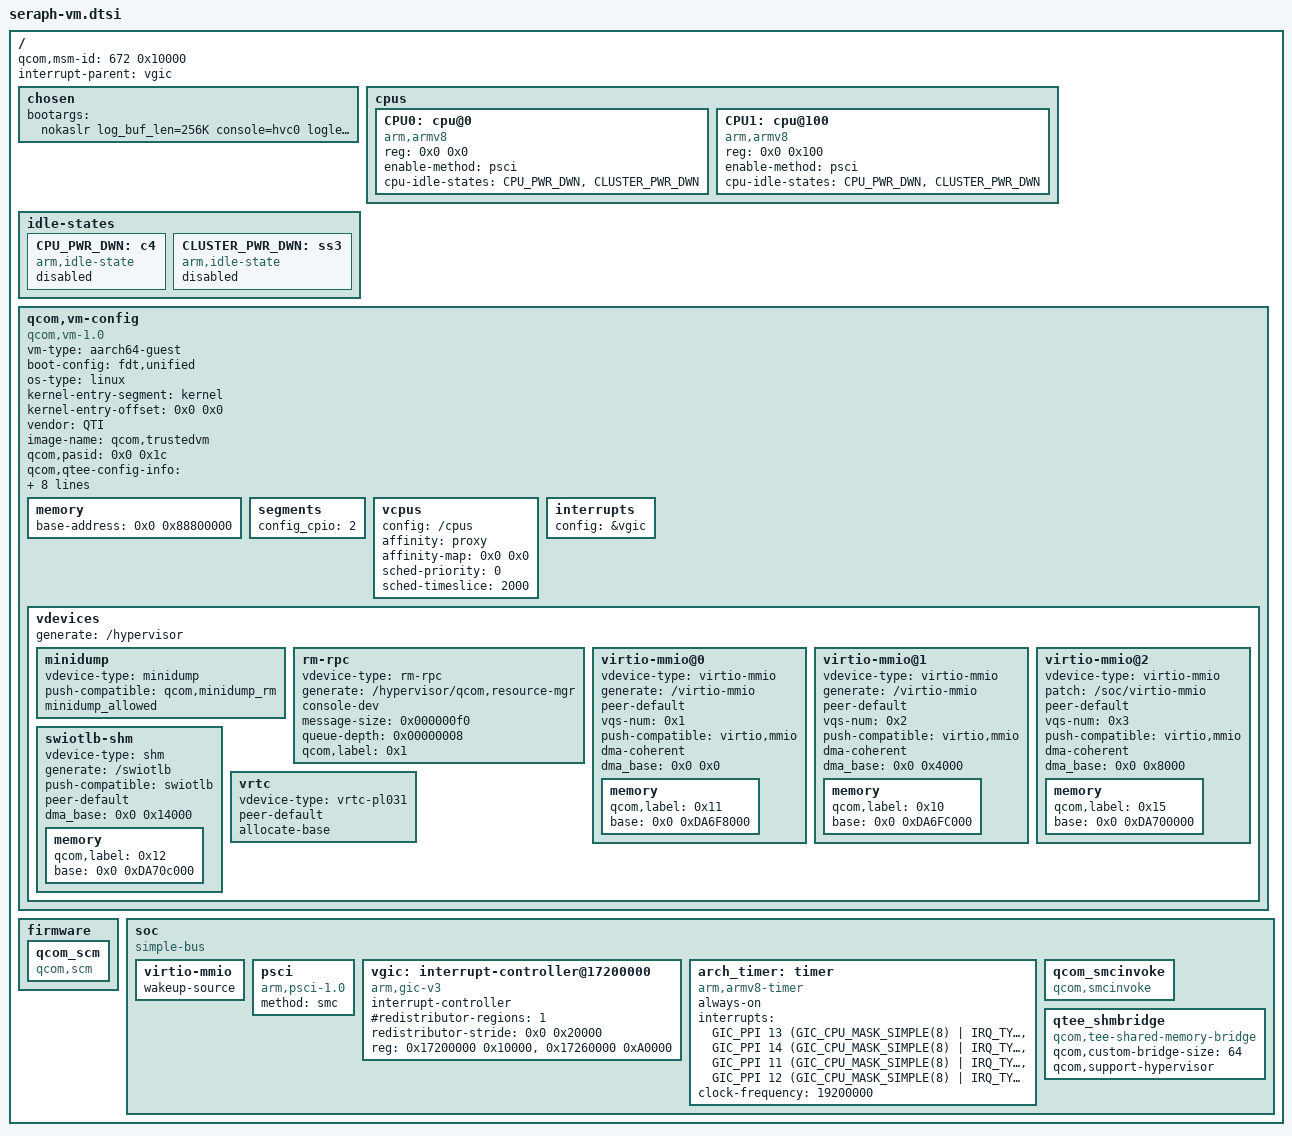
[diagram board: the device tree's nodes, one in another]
#include <dt-bindings/interrupt-controller/arm-gic.h>
#include <dt-bindings/clock/qcom,gcc-seraph.h>

/ {
	#address-cells = <0x2>;
	#size-cells = <0x2>;
	qcom,msm-id = <672 0x10000>;
	interrupt-parent = <&vgic>;
	chosen {
		bootargs = "nokaslr log_buf_len=256K console=hvc0 loglevel=8 swiotlb=noforce";
	};

	cpus {
		#address-cells = <0x2>;
		#size-cells = <0x0>;
		CPU0: cpu@0 {
			compatible = "arm,armv8";
			reg = <0x0 0x0>;
			device_type = "cpu";
			enable-method = "psci";
			cpu-idle-states = <&CPU_PWR_DWN
					   &CLUSTER_PWR_DWN>;
		};

		CPU1: cpu@100 {
			compatible = "arm,armv8";
			reg = <0x0 0x100>;
			device_type = "cpu";
			enable-method = "psci";
			cpu-idle-states = <&CPU_PWR_DWN
					   &CLUSTER_PWR_DWN>;
		};
	};

	idle-states {
		CPU_PWR_DWN: c4 {  /* Using Medium C4 latencies */
			compatible = "arm,idle-state";
			status = "disabled";
		};

		CLUSTER_PWR_DWN: ss3 { /* C4+CL5+SS3 */
			compatible = "arm,idle-state";
			status = "disabled";
		};
	};

	qcom,vm-config {
		compatible = "qcom,vm-1.0";
		vm-type = "aarch64-guest";
		boot-config = "fdt,unified";
		os-type = "linux";
		kernel-entry-segment = "kernel";
		kernel-entry-offset = <0x0 0x0>;
		vendor = "QTI";
		image-name = "qcom,trustedvm";
		qcom,pasid = <0x0 0x1c>;
		qcom,qtee-config-info = "p=3,9,C,39,77,78,7C,8F,96,97,C8,FE,10C,11B,159,199,47E,7F1,CDF;";
		qcom,secdomain-ids = <45>;
		qcom,primary-vm-index = <0>;
		vm-uri = "vmuid/trusted-ui";
		vm-guid = "598085da-c516-5b25-a9c1-927a02819770";
		qcom,sensitive;
		vm-attrs = "context-dump", "crash-restart";
		/* For LEVM por usecases is QUP1_SE4 and QUP2_SE7.
		 * QUP1_SE4: GPII5 : IRQ_316
		 * QUP2_SE7: GPII5 : IRQ_625
		 *
		if you need this, add IRQ here
		gic-irq-ranges = <316 316
				  625 625
				  279 279>;
		*/
		gic-irq-ranges = <>;
		memory {
			#address-cells = <0x2>;
			#size-cells = <0x0>;
			/*
			 * IPA address linux image is loaded at. Must be within
			 * first 1GB due to memory hotplug requirement.
			 */
			base-address = <0x0 0x88800000 >;
		};

		segments {
			config_cpio = <2>;
		};

		vcpus {
			config = "/cpus";
			affinity = "proxy";
			affinity-map = <0x0 0x0>;
			sched-priority = <0>;       /* relative to PVM */
			sched-timeslice = <2000>;   /* in ms */
		};

		interrupts {
			config = &vgic;
		};

		vdevices {
			generate = "/hypervisor";
			minidump {
				vdevice-type = "minidump";
				push-compatible = "qcom,minidump_rm";
				minidump_allowed;
			};

			rm-rpc {
				vdevice-type = "rm-rpc";
				generate = "/hypervisor/qcom,resource-mgr";
				console-dev;
				message-size = <0x000000f0>;
				queue-depth = <0x00000008>;
				qcom,label = <0x1>;
			};

			virtio-mmio@0 {
				vdevice-type = "virtio-mmio";
				generate = "/virtio-mmio";
				peer-default;
				vqs-num = <0x1>;
				push-compatible = "virtio,mmio";
				dma-coherent;
				dma_base = <0x0 0x0>;
				memory {
					qcom,label = <0x11>;			//for persist.img
					#address-cells = <0x2>;
					base = <0x0 0xDA6F8000>;
				};
			};

			virtio-mmio@1 {
				vdevice-type = "virtio-mmio";
				generate = "/virtio-mmio";
				peer-default;
				vqs-num = <0x2>;
				push-compatible = "virtio,mmio";
				dma-coherent;
				dma_base = <0x0 0x4000>;
				memory {
					qcom,label = <0x10>;			//for system.img
					#address-cells = <0x2>;
					base = <0x0 0xDA6FC000>;
				};
			};

			virtio-mmio@2 {
				vdevice-type = "virtio-mmio";
				patch = "/soc/virtio-mmio";
				peer-default;
				vqs-num = <0x3>;
				push-compatible = "virtio,mmio";
				dma-coherent;
				dma_base = <0x0 0x8000>;
				memory {
					qcom,label = <0x15>;			//for virtio-vsock
					#address-cells = <0x2>;
					base = <0x0 0xDA700000>;
				};
			};

			swiotlb-shm {
				vdevice-type = "shm";
				generate = "/swiotlb";
				push-compatible = "swiotlb";
				peer-default;
				dma_base = <0x0 0x14000>;
				memory {
					qcom,label = <0x12>;
					#address-cells = <0x2>;
					base = <0x0 0xDA70c000>;
				};
			};

			vrtc {
				vdevice-type = "vrtc-pl031";
				peer-default;
				allocate-base;
			};
		};
	};

	firmware: firmware {
		qcom_scm: qcom_scm {
			compatible = "qcom,scm";
		};
	};

	soc: soc { };

};

&soc {
	#address-cells = <1>;
	#size-cells = <1>;
	ranges = <0 0 0 0xffffffff>;
	compatible = "simple-bus";
	virtio-mmio {
		wakeup-source;
	};

	psci {
		compatible = "arm,psci-1.0";
		method = "smc";
	};

	vgic: interrupt-controller@17200000 {
		compatible = "arm,gic-v3";
		#interrupt-cells = <3>;
		interrupt-controller;
		#redistributor-regions = <1>;
		redistributor-stride = <0x0 0x20000>;
		reg = <0x17200000 0x10000>,       /* GICD */
		     <0x17260000 0xA0000>;       /* GICR * 5 */
	};

	arch_timer: timer {
		compatible = "arm,armv8-timer";
		always-on;
		interrupts = <GIC_PPI 13 (GIC_CPU_MASK_SIMPLE(8) | IRQ_TYPE_LEVEL_LOW)>,
			     <GIC_PPI 14 (GIC_CPU_MASK_SIMPLE(8) | IRQ_TYPE_LEVEL_LOW)>,
			     <GIC_PPI 11 (GIC_CPU_MASK_SIMPLE(8) | IRQ_TYPE_LEVEL_LOW)>,
			     <GIC_PPI 12 (GIC_CPU_MASK_SIMPLE(8) | IRQ_TYPE_LEVEL_LOW)>;
		clock-frequency = <19200000>;
	};

	qcom_smcinvoke {
		compatible = "qcom,smcinvoke";
	};

	qtee_shmbridge {
		compatible = "qcom,tee-shared-memory-bridge";
		qcom,custom-bridge-size = <64>;
		qcom,support-hypervisor;
	};
};
